# A8107M register map
Vendor: Amiccom Electronics Co., Ltd.; Series: A8107M; File version: 1.0
CPU: CM0 r0p0, little endian, no MPU, no FPU, 2 interrupt priority bits
Registers are 32-bit, read-write, reset 0x0 unless marked. A register's access mark holds for its fields unless they carry their own. Offsets are from the block's base; [hi:lo] are bit positions.

## GPIO0 (part 1 of 2) — General Purpose I/O
Base 0x40010000
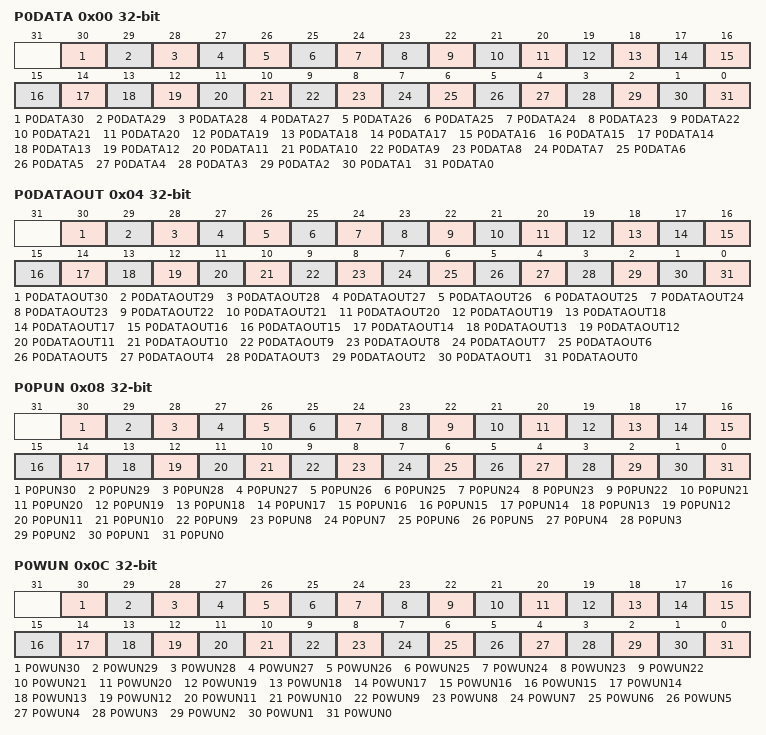
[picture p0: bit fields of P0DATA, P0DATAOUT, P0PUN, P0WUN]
0x00 P0DATA — Port 0 Data Register
  [30] P0DATA30 — Data of GPIO0.30
    0=GPIO0.30 is 0; 1=GPIO0.30 is 1
  [29] P0DATA29 — Data of GPIO0.29
    0=GPIO0.29 is 0; 1=GPIO0.29 is 1
  [28] P0DATA28 — Data of GPIO0.28
    0=GPIO0.28 is 0; 1=GPIO0.28 is 1
  [27] P0DATA27 — Data of GPIO0.27
    0=GPIO0.27 is 0; 1=GPIO0.27 is 1
  [26] P0DATA26 — Data of GPIO0.26
    0=GPIO0.26 is 0; 1=GPIO0.26 is 1
  [25] P0DATA25 — Data of GPIO0.25
    0=GPIO0.25 is 0; 1=GPIO0.25 is 1
  [24] P0DATA24 — Data of GPIO0.24
    0=GPIO0.24 is 0; 1=GPIO0.24 is 1
  [23] P0DATA23 — Data of GPIO0.23
    0=GPIO0.23 is 0; 1=GPIO0.23 is 1
  [22] P0DATA22 — Data of GPIO0.22
    0=GPIO0.22 is 0; 1=GPIO0.22 is 1
  [21] P0DATA21 — Data of GPIO0.21
    0=GPIO0.21 is 0; 1=GPIO0.21 is 1
  [20] P0DATA20 — Data of GPIO0.20
    0=GPIO0.20 is 0; 1=GPIO0.20 is 1
  [19] P0DATA19 — Data of GPIO0.19
    0=GPIO0.19 is 0; 1=GPIO0.19 is 1
  [18] P0DATA18 — Data of GPIO0.18
    0=GPIO0.18 is 0; 1=GPIO0.18 is 1
  [17] P0DATA17 — Data of GPIO0.17
    0=GPIO0.17 is 0; 1=GPIO0.17 is 1
  [16] P0DATA16 — Data of GPIO0.16
    0=GPIO0.16 is 0; 1=GPIO0.16 is 1
  [15] P0DATA15 — Data of GPIO0.15
    0=GPIO0.15 is 0; 1=GPIO0.15 is 1
  [14] P0DATA14 — Data of GPIO0.14
    0=GPIO0.14 is 0; 1=GPIO0.14 is 1
  [13] P0DATA13 — Data of GPIO0.13
    0=GPIO0.13 is 0; 1=GPIO0.13 is 1
  [12] P0DATA12 — Data of GPIO0.12
    0=GPIO0.12 is 0; 1=GPIO0.12 is 1
  [11] P0DATA11 — Data of GPIO0.11
    0=GPIO0.11 is 0; 1=GPIO0.11 is 1
  [10] P0DATA10 — Data of GPIO0.10
    0=GPIO0.10 is 0; 1=GPIO0.10 is 1
  [9] P0DATA9 — Data of GPIO0.9
    0=GPIO0.9 is 0; 1=GPIO0.9 is 1
  [8] P0DATA8 — Data of GPIO0.8
    0=GPIO0.8 is 0; 1=GPIO0.8 is 1
  [7] P0DATA7 — Data of GPIO0.7
    0=GPIO0.7 is 0; 1=GPIO0.7 is 1
  [6] P0DATA6 — Data of GPIO0.6
    0=GPIO0.6 is 0; 1=GPIO0.6 is 1
  [5] P0DATA5 — Data of GPIO0.5
    0=GPIO0.5 is 0; 1=GPIO0.5 is 1
  [4] P0DATA4 — Data of GPIO0.4
    0=GPIO0.4 is 0; 1=GPIO0.4 is 1
  [3] P0DATA3 — Data of GPIO0.3
    0=GPIO0.3 is 0; 1=GPIO0.3 is 1
  [2] P0DATA2 — Data of GPIO0.2
    0=GPIO0.2 is 0; 1=GPIO0.2 is 1
  [1] P0DATA1 — Data of GPIO0.1
    0=GPIO0.1 is 0; 1=GPIO0.1 is 1
  [0] P0DATA0 — Data of GPIO0.0
    0=GPIO0.0 is 0; 1=GPIO0.0 is 1
0x00 P0DATA_PIN (reset mask 0x7FFFFFFF) (alternate view of P0DATA) — Port 0 Data Register access by Pin
0x04 P0DATAOUT — Port 0 Data Out Register
  [30] P0DATAOUT30 — Data Out of GPIO0.30
    0=GPIO0.30 is 0; 1=GPIO0.30 is 1
  [29] P0DATAOUT29 — Data Out of GPIO0.29
    0=GPIO0.29 is 0; 1=GPIO0.29 is 1
  [28] P0DATAOUT28 — Data Out of GPIO0.28
    0=GPIO0.28 is 0; 1=GPIO0.28 is 1
  [27] P0DATAOUT27 — Data Out of GPIO0.27
    0=GPIO0.27 is 0; 1=GPIO0.27 is 1
  [26] P0DATAOUT26 — Data Out of GPIO0.26
    0=GPIO0.26 is 0; 1=GPIO0.26 is 1
  [25] P0DATAOUT25 — Data Out of GPIO0.25
    0=GPIO0.25 is 0; 1=GPIO0.25 is 1
  [24] P0DATAOUT24 — Data Out of GPIO0.24
    0=GPIO0.24 is 0; 1=GPIO0.24 is 1
  [23] P0DATAOUT23 — Data Out of GPIO0.23
    0=GPIO0.23 is 0; 1=GPIO0.23 is 1
  [22] P0DATAOUT22 — Data Out of GPIO0.22
    0=GPIO0.22 is 0; 1=GPIO0.22 is 1
  [21] P0DATAOUT21 — Data Out of GPIO0.21
    0=GPIO0.21 is 0; 1=GPIO0.21 is 1
  [20] P0DATAOUT20 — Data Out of GPIO0.20
    0=GPIO0.20 is 0; 1=GPIO0.20 is 1
  [19] P0DATAOUT19 — Data Out of GPIO0.19
    0=GPIO0.19 is 0; 1=GPIO0.19 is 1
  [18] P0DATAOUT18 — Data Out of GPIO0.18
    0=GPIO0.18 is 0; 1=GPIO0.18 is 1
  [17] P0DATAOUT17 — Data Out of GPIO0.17
    0=GPIO0.17 is 0; 1=GPIO0.17 is 1
  [16] P0DATAOUT16 — Data Out of GPIO0.16
    0=GPIO0.16 is 0; 1=GPIO0.16 is 1
  [15] P0DATAOUT15 — Data Out of GPIO0.15
    0=GPIO0.15 is 0; 1=GPIO0.15 is 1
  [14] P0DATAOUT14 — Data Out of GPIO0.14
    0=GPIO0.14 is 0; 1=GPIO0.14 is 1
  [13] P0DATAOUT13 — Data Out of GPIO0.13
    0=GPIO0.13 is 0; 1=GPIO0.13 is 1
  [12] P0DATAOUT12 — Data Out of GPIO0.12
    0=GPIO0.12 is 0; 1=GPIO0.12 is 1
  [11] P0DATAOUT11 — Data Out of GPIO0.11
    0=GPIO0.11 is 0; 1=GPIO0.11 is 1
  [10] P0DATAOUT10 — Data Out of GPIO0.10
    0=GPIO0.10 is 0; 1=GPIO0.10 is 1
  [9] P0DATAOUT9 — Data Out of GPIO0.9
    0=GPIO0.9 is 0; 1=GPIO0.9 is 1
  [8] P0DATAOUT8 — Data Out of GPIO0.8
    0=GPIO0.8 is 0; 1=GPIO0.8 is 1
  [7] P0DATAOUT7 — Data Out of GPIO0.7
    0=GPIO0.7 is 0; 1=GPIO0.7 is 1
  [6] P0DATAOUT6 — Data Out of GPIO0.6
    0=GPIO0.6 is 0; 1=GPIO0.6 is 1
  [5] P0DATAOUT5 — Data Out of GPIO0.5
    0=GPIO0.5 is 0; 1=GPIO0.5 is 1
  [4] P0DATAOUT4 — Data Out of GPIO0.4
    0=GPIO0.4 is 0; 1=GPIO0.4 is 1
  [3] P0DATAOUT3 — Data Out of GPIO0.3
    0=GPIO0.3 is 0; 1=GPIO0.3 is 1
  [2] P0DATAOUT2 — Data Out of GPIO0.2
    0=GPIO0.2 is 0; 1=GPIO0.2 is 1
  [1] P0DATAOUT1 — Data Out of GPIO0.1
    0=GPIO0.1 is 0; 1=GPIO0.1 is 1
  [0] P0DATAOUT0 — Data Out of GPIO0.0
    0=GPIO0.0 is 0; 1=GPIO0.0 is 1
0x04 P0DATAOUT_PIN (reset mask 0x7FFFFFFF) (alternate view of P0DATAOUT) — Port 0 Data Out Register access by Pin
0x08 P0PUN — Port 0 Pull Up Not Register
  [30] P0PUN30 — Pull Up of GPIO0.30
    0=Pull Up of GPIO0.30 is enable; 1=Pull Up of GPIO0.30 is disable
  [29] P0PUN29 — Pull Up of GPIO0.29
    0=Pull Up of GPIO0.29 is enable; 1=Pull Up of GPIO0.29 is disable
  [28] P0PUN28 — Pull Up of GPIO0.28
    0=Pull Up of GPIO0.28 is enable; 1=Pull Up of GPIO0.28 is disable
  [27] P0PUN27 — Pull Up of GPIO0.27
    0=Pull Up of GPIO0.27 is enable; 1=Pull Up of GPIO0.27 is disable
  [26] P0PUN26 — Pull Up of GPIO0.26
    0=Pull Up of GPIO0.26 is enable; 1=Pull Up of GPIO0.26 is disable
  [25] P0PUN25 — Pull Up of GPIO0.25
    0=Pull Up of GPIO0.25 is enable; 1=Pull Up of GPIO0.25 is disable
  [24] P0PUN24 — Pull Up of GPIO0.24
    0=Pull Up of GPIO0.24 is enable; 1=Pull Up of GPIO0.24 is disable
  [23] P0PUN23 — Pull Up of GPIO0.23
    0=Pull Up of GPIO0.23 is enable; 1=Pull Up of GPIO0.23 is disable
  [22] P0PUN22 — Pull Up of GPIO0.22
    0=Pull Up of GPIO0.22 is enable; 1=Pull Up of GPIO0.22 is disable
  [21] P0PUN21 — Pull Up of GPIO0.21
    0=Pull Up of GPIO0.21 is enable; 1=Pull Up of GPIO0.21 is disable
  [20] P0PUN20 — Pull Up of GPIO0.20
    0=Pull Up of GPIO0.20 is enable; 1=Pull Up of GPIO0.20 is disable
  [19] P0PUN19 — Pull Up of GPIO0.19
    0=Pull Up of GPIO0.19 is enable; 1=Pull Up of GPIO0.19 is disable
  [18] P0PUN18 — Pull Up of GPIO0.18
    0=Pull Up of GPIO0.18 is enable; 1=Pull Up of GPIO0.18 is disable
  [17] P0PUN17 — Pull Up of GPIO0.17
    0=Pull Up of GPIO0.17 is enable; 1=Pull Up of GPIO0.17 is disable
  [16] P0PUN16 — Pull Up of GPIO0.16
    0=Pull Up of GPIO0.16 is enable; 1=Pull Up of GPIO0.16 is disable
  [15] P0PUN15 — Pull Up of GPIO0.15
    0=Pull Up of GPIO0.15 is enable; 1=Pull Up of GPIO0.15 is disable
  [14] P0PUN14 — Pull Up of GPIO0.14
    0=Pull Up of GPIO0.14 is enable; 1=Pull Up of GPIO0.14 is disable
  [13] P0PUN13 — Pull Up of GPIO0.13
    0=Pull Up of GPIO0.13 is enable; 1=Pull Up of GPIO0.13 is disable
  [12] P0PUN12 — Pull Up of GPIO0.12
    0=Pull Up of GPIO0.12 is enable; 1=Pull Up of GPIO0.12 is disable
  [11] P0PUN11 — Pull Up of GPIO0.11
    0=Pull Up of GPIO0.11 is enable; 1=Pull Up of GPIO0.11 is disable
  [10] P0PUN10 — Pull Up of GPIO0.10
    0=Pull Up of GPIO0.10 is enable; 1=Pull Up of GPIO0.10 is disable
  [9] P0PUN9 — Pull Up of GPIO0.9
    0=Pull Up of GPIO0.9 is enable; 1=Pull Up of GPIO0.9 is disable
  [8] P0PUN8 — Pull Up of GPIO0.8
    0=Pull Up of GPIO0.8 is enable; 1=Pull Up of GPIO0.8 is disable
  [7] P0PUN7 — Pull Up of GPIO0.7
    0=Pull Up of GPIO0.7 is enable; 1=Pull Up of GPIO0.7 is disable
  [6] P0PUN6 — Pull Up of GPIO0.6
    0=Pull Up of GPIO0.6 is enable; 1=Pull Up of GPIO0.6 is disable
  [5] P0PUN5 — Pull Up of GPIO0.5
    0=Pull Up of GPIO0.5 is enable; 1=Pull Up of GPIO0.5 is disable
  [4] P0PUN4 — Pull Up of GPIO0.4
    0=Pull Up of GPIO0.4 is enable; 1=Pull Up of GPIO0.4 is disable
  [3] P0PUN3 — Pull Up of GPIO0.3
    0=Pull Up of GPIO0.3 is enable; 1=Pull Up of GPIO0.3 is disable
  [2] P0PUN2 — Pull Up of GPIO0.2
    0=Pull Up of GPIO0.2 is enable; 1=Pull Up of GPIO0.2 is disable
  [1] P0PUN1 — Pull Up of GPIO0.1
    0=Pull Up of GPIO0.1 is enable; 1=Pull Up of GPIO0.1 is disable
  [0] P0PUN0 — Pull Up of GPIO0.0
    0=Pull Up of GPIO0.0 is enable; 1=Pull Up of GPIO0.0 is disable
0x08 P0PUN_PIN (reset mask 0x7FFFFFFF) (alternate view of P0PUN) — Port 0 Pull Up Not Register access by Pin
0x0C P0WUN — Port 0 Wakeup Enable Not Register
  [30] P0WUN30 — Wakeup of GPIO0.30
    0=Wakeup of GPIO0.30 is enable; 1=Wakeup of GPIO0.30 is disable
  [29] P0WUN29 — Wakeup of GPIO0.29
    0=Wakeup of GPIO0.29 is enable; 1=Wakeup of GPIO0.29 is disable
  [28] P0WUN28 — Wakeup of GPIO0.28
    0=Wakeup of GPIO0.28 is enable; 1=Wakeup of GPIO0.28 is disable
  [27] P0WUN27 — Wakeup of GPIO0.27
    0=Wakeup of GPIO0.27 is enable; 1=Wakeup of GPIO0.27 is disable
  [26] P0WUN26 — Wakeup of GPIO0.26
    0=Wakeup of GPIO0.26 is enable; 1=Wakeup of GPIO0.26 is disable
  [25] P0WUN25 — Wakeup of GPIO0.25
    0=Wakeup of GPIO0.25 is enable; 1=Wakeup of GPIO0.25 is disable
  [24] P0WUN24 — Wakeup of GPIO0.24
    0=Wakeup of GPIO0.24 is enable; 1=Wakeup of GPIO0.24 is disable
  [23] P0WUN23 — Wakeup of GPIO0.23
    0=Wakeup of GPIO0.23 is enable; 1=Wakeup of GPIO0.23 is disable
  [22] P0WUN22 — Wakeup of GPIO0.22
    0=Wakeup of GPIO0.22 is enable; 1=Wakeup of GPIO0.22 is disable
  [21] P0WUN21 — Wakeup of GPIO0.21
    0=Wakeup of GPIO0.21 is enable; 1=Wakeup of GPIO0.21 is disable
  [20] P0WUN20 — Wakeup of GPIO0.20
    0=Wakeup of GPIO0.20 is enable; 1=Wakeup of GPIO0.20 is disable
  [19] P0WUN19 — Wakeup of GPIO0.19
    0=Wakeup of GPIO0.19 is enable; 1=Wakeup of GPIO0.19 is disable
  [18] P0WUN18 — Wakeup of GPIO0.18
    0=Wakeup of GPIO0.18 is enable; 1=Wakeup of GPIO0.18 is disable
  [17] P0WUN17 — Wakeup of GPIO0.17
    0=Wakeup of GPIO0.17 is enable; 1=Wakeup of GPIO0.17 is disable
  [16] P0WUN16 — Wakeup of GPIO0.16
    0=Wakeup of GPIO0.16 is enable; 1=Wakeup of GPIO0.16 is disable
  [15] P0WUN15 — Wakeup of GPIO0.15
    0=Wakeup of GPIO0.15 is enable; 1=Wakeup of GPIO0.15 is disable
  [14] P0WUN14 — Wakeup of GPIO0.14
    0=Wakeup of GPIO0.14 is enable; 1=Wakeup of GPIO0.14 is disable
  [13] P0WUN13 — Wakeup of GPIO0.13
    0=Wakeup of GPIO0.13 is enable; 1=Wakeup of GPIO0.13 is disable
  [12] P0WUN12 — Wakeup of GPIO0.12
    0=Wakeup of GPIO0.12 is enable; 1=Wakeup of GPIO0.12 is disable
  [11] P0WUN11 — Wakeup of GPIO0.11
    0=Wakeup of GPIO0.11 is enable; 1=Wakeup of GPIO0.11 is disable
  [10] P0WUN10 — Wakeup of GPIO0.10
    0=Wakeup of GPIO0.10 is enable; 1=Wakeup of GPIO0.10 is disable
  [9] P0WUN9 — Wakeup of GPIO0.9
    0=Wakeup of GPIO0.9 is enable; 1=Wakeup of GPIO0.9 is disable
  [8] P0WUN8 — Wakeup of GPIO0.8
    0=Wakeup of GPIO0.8 is enable; 1=Wakeup of GPIO0.8 is disable
  [7] P0WUN7 — Wakeup of GPIO0.7
    0=Wakeup of GPIO0.7 is enable; 1=Wakeup of GPIO0.7 is disable
  [6] P0WUN6 — Wakeup of GPIO0.6
    0=Wakeup of GPIO0.6 is enable; 1=Wakeup of GPIO0.6 is disable
  [5] P0WUN5 — Wakeup of GPIO0.5
    0=Wakeup of GPIO0.5 is enable; 1=Wakeup of GPIO0.5 is disable
  [4] P0WUN4 — Wakeup of GPIO0.4
    0=Wakeup of GPIO0.4 is enable; 1=Wakeup of GPIO0.4 is disable
  [3] P0WUN3 — Wakeup of GPIO0.3
    0=Wakeup of GPIO0.3 is enable; 1=Wakeup of GPIO0.3 is disable
  [2] P0WUN2 — Wakeup of GPIO0.2
    0=Wakeup of GPIO0.2 is enable; 1=Wakeup of GPIO0.2 is disable
  [1] P0WUN1 — Wakeup of GPIO0.1
    0=Wakeup of GPIO0.1 is enable; 1=Wakeup of GPIO0.1 is disable
  [0] P0WUN0 — Wakeup of GPIO0.0
    0=Wakeup of GPIO0.0 is enable; 1=Wakeup of GPIO0.0 is disable
0x0C P0WUN_PIN (reset mask 0x7FFFFFFF) (alternate view of P0WUN) — Port 0 Wakeup Enable Not Register access by Pin
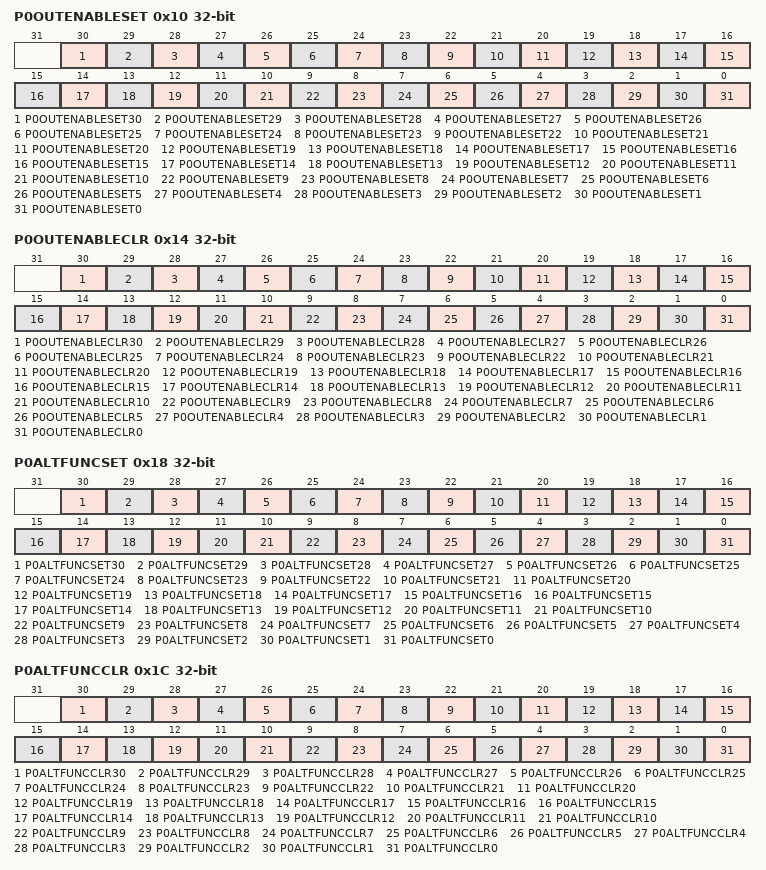
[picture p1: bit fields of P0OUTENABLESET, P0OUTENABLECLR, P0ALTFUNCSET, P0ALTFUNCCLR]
0x10 P0OUTENABLESET — Port 0 Output Enable Set Register
  [30] P0OUTENABLESET30 — Output Enable Clear of GPIO0.30
    0=No effect; 1=Output Enable Clear of GPIO0.30
  [29] P0OUTENABLESET29 — Output Enable Clear of GPIO0.29
    0=No effect; 1=Output Enable Clear of GPIO0.29
  [28] P0OUTENABLESET28 — Output Enable Clear of GPIO0.28
    0=No effect; 1=Output Enable Clear of GPIO0.28
  [27] P0OUTENABLESET27 — Output Enable Clear of GPIO0.27
    0=No effect; 1=No effect
  [26] P0OUTENABLESET26 — Output Enable Clear of GPIO0.26
    0=No effect; 1=Output Enable Clear of GPIO0.26
  [25] P0OUTENABLESET25 — Output Enable Clear of GPIO0.25
    0=No effect; 1=Output Enable Clear of GPIO0.25
  [24] P0OUTENABLESET24 — Output Enable Clear of GPIO0.24
    0=No effect; 1=Output Enable Clear of GPIO0.24
  [23] P0OUTENABLESET23 — Output Enable Clear of GPIO0.23
    0=No effect; 1=Output Enable Clear of GPIO0.23
  [22] P0OUTENABLESET22 — Output Enable Clear of GPIO0.22
    0=No effect; 1=Output Enable Clear of GPIO0.22
  [21] P0OUTENABLESET21 — Output Enable Clear of GPIO0.21
    0=No effect; 1=Output Enable Clear of GPIO0.21
  [20] P0OUTENABLESET20 — Output Enable Clear of GPIO0.20
    0=No effect; 1=Output Enable Clear of GPIO0.20
  [19] P0OUTENABLESET19 — Output Enable Clear of GPIO0.19
    0=No effect; 1=Output Enable Clear of GPIO0.19
  [18] P0OUTENABLESET18 — Output Enable Clear of GPIO0.18
    0=No effect; 1=Output Enable Clear of GPIO0.18
  [17] P0OUTENABLESET17 — Output Enable Clear of GPIO0.17
    0=No effect; 1=Output Enable Clear of GPIO0.17
  [16] P0OUTENABLESET16 — Output Enable Clear of GPIO0.16
    0=No effect; 1=Output Enable Clear of GPIO0.16
  [15] P0OUTENABLESET15 — Output Enable Clear of GPIO0.15
    0=No effect; 1=Output Enable Clear of GPIO0.15
  [14] P0OUTENABLESET14 — Output Enable Clear of GPIO0.14
    0=No effect; 1=Output Enable Clear of GPIO0.14
  [13] P0OUTENABLESET13 — Output Enable Clear of GPIO0.13
    0=No effect; 1=Output Enable Clear of GPIO0.13
  [12] P0OUTENABLESET12 — Output Enable Clear of GPIO0.12
    0=No effect; 1=Output Enable Clear of GPIO0.12
  [11] P0OUTENABLESET11 — Output Enable Clear of GPIO0.11
    0=No effect; 1=Output Enable Clear of GPIO0.11
  [10] P0OUTENABLESET10 — Output Enable Clear of GPIO0.10
    0=No effect; 1=Output Enable Clear of GPIO0.10
  [9] P0OUTENABLESET9 — Output Enable Clear of GPIO0.9
    0=No effect; 1=Output Enable Clear of GPIO0.9
  [8] P0OUTENABLESET8 — Output Enable Clear of GPIO0.8
    0=No effect; 1=Output Enable Clear of GPIO0.8
  [7] P0OUTENABLESET7 — Output Enable Clear of GPIO0.7
    0=No effect; 1=Output Enable Clear of GPIO0.7
  [6] P0OUTENABLESET6 — Output Enable Clear of GPIO0.6
    0=No effect; 1=Output Enable Clear of GPIO0.6
  [5] P0OUTENABLESET5 — Output Enable Clear of GPIO0.5
    0=No effect; 1=Output Enable Clear of GPIO0.5
  [4] P0OUTENABLESET4 — Output Enable Clear of GPIO0.4
    0=No effect; 1=Output Enable Clear of GPIO0.4
  [3] P0OUTENABLESET3 — Output Enable Clear of GPIO0.3
    0=No effect; 1=Output Enable Clear of GPIO0.3
  [2] P0OUTENABLESET2 — Output Enable Clear of GPIO0.2
    0=No effect; 1=Output Enable Clear of GPIO0.2
  [1] P0OUTENABLESET1 — Output Enable Clear of GPIO0.1
    0=No effect; 1=Output Enable Clear of GPIO0.1
  [0] P0OUTENABLESET0 — Output Enable Clear of GPIO0.0
    0=No effect; 1=Output Enable Clear of GPIO0.0
0x14 P0OUTENABLECLR — Port 0 Output Enable Clear Register
  [30] P0OUTENABLECLR30 — Output Enable Clear of GPIO0.30
    0=No effect; 1=Output Enable Clear of GPIO0.30
  [29] P0OUTENABLECLR29 — Output Enable Clear of GPIO0.29
    0=No effect; 1=Output Enable Clear of GPIO0.29
  [28] P0OUTENABLECLR28 — Output Enable Clear of GPIO0.28
    0=No effect; 1=Output Enable Clear of GPIO0.28
  [27] P0OUTENABLECLR27 — Output Enable Clear of GPIO0.27
    0=No effect; 1=No effect
  [26] P0OUTENABLECLR26 — Output Enable Clear of GPIO0.26
    0=No effect; 1=Output Enable Clear of GPIO0.26
  [25] P0OUTENABLECLR25 — Output Enable Clear of GPIO0.25
    0=No effect; 1=Output Enable Clear of GPIO0.25
  [24] P0OUTENABLECLR24 — Output Enable Clear of GPIO0.24
    0=No effect; 1=Output Enable Clear of GPIO0.24
  [23] P0OUTENABLECLR23 — Output Enable Clear of GPIO0.23
    0=No effect; 1=Output Enable Clear of GPIO0.23
  [22] P0OUTENABLECLR22 — Output Enable Clear of GPIO0.22
    0=No effect; 1=Output Enable Clear of GPIO0.22
  [21] P0OUTENABLECLR21 — Output Enable Clear of GPIO0.21
    0=No effect; 1=Output Enable Clear of GPIO0.21
  [20] P0OUTENABLECLR20 — Output Enable Clear of GPIO0.20
    0=No effect; 1=Output Enable Clear of GPIO0.20
  [19] P0OUTENABLECLR19 — Output Enable Clear of GPIO0.19
    0=No effect; 1=Output Enable Clear of GPIO0.19
  [18] P0OUTENABLECLR18 — Output Enable Clear of GPIO0.18
    0=No effect; 1=Output Enable Clear of GPIO0.18
  [17] P0OUTENABLECLR17 — Output Enable Clear of GPIO0.17
    0=No effect; 1=Output Enable Clear of GPIO0.17
  [16] P0OUTENABLECLR16 — Output Enable Clear of GPIO0.16
    0=No effect; 1=Output Enable Clear of GPIO0.16
  [15] P0OUTENABLECLR15 — Output Enable Clear of GPIO0.15
    0=No effect; 1=Output Enable Clear of GPIO0.15
  [14] P0OUTENABLECLR14 — Output Enable Clear of GPIO0.14
    0=No effect; 1=Output Enable Clear of GPIO0.14
  [13] P0OUTENABLECLR13 — Output Enable Clear of GPIO0.13
    0=No effect; 1=Output Enable Clear of GPIO0.13
  [12] P0OUTENABLECLR12 — Output Enable Clear of GPIO0.12
    0=No effect; 1=Output Enable Clear of GPIO0.12
  [11] P0OUTENABLECLR11 — Output Enable Clear of GPIO0.11
    0=No effect; 1=Output Enable Clear of GPIO0.11
  [10] P0OUTENABLECLR10 — Output Enable Clear of GPIO0.10
    0=No effect; 1=Output Enable Clear of GPIO0.10
  [9] P0OUTENABLECLR9 — Output Enable Clear of GPIO0.9
    0=No effect; 1=Output Enable Clear of GPIO0.9
  [8] P0OUTENABLECLR8 — Output Enable Clear of GPIO0.8
    0=No effect; 1=Output Enable Clear of GPIO0.8
  [7] P0OUTENABLECLR7 — Output Enable Clear of GPIO0.7
    0=No effect; 1=Output Enable Clear of GPIO0.7
  [6] P0OUTENABLECLR6 — Output Enable Clear of GPIO0.6
    0=No effect; 1=Output Enable Clear of GPIO0.6
  [5] P0OUTENABLECLR5 — Output Enable Clear of GPIO0.5
    0=No effect; 1=Output Enable Clear of GPIO0.5
  [4] P0OUTENABLECLR4 — Output Enable Clear of GPIO0.4
    0=No effect; 1=Output Enable Clear of GPIO0.4
  [3] P0OUTENABLECLR3 — Output Enable Clear of GPIO0.3
    0=No effect; 1=Output Enable Clear of GPIO0.3
  [2] P0OUTENABLECLR2 — Output Enable Clear of GPIO0.2
    0=No effect; 1=Output Enable Clear of GPIO0.2
  [1] P0OUTENABLECLR1 — Output Enable Clear of GPIO0.1
    0=No effect; 1=Output Enable Clear of GPIO0.1
  [0] P0OUTENABLECLR0 — Output Enable Clear of GPIO0.0
    0=No effect; 1=Output enable clear of GPIO0.0
0x18 P0ALTFUNCSET — Port 0 Alternative Function Set Register
  [30] P0ALTFUNCSET30 — Alternative Function Set of GPIO0.30
    0=No effect; 1=Alternative Function Set of GPIO0.30
  [29] P0ALTFUNCSET29 — Alternative Function Set of GPIO0.29
    0=No effect; 1=Alternative Function Set of GPIO0.29
  [28] P0ALTFUNCSET28 — Alternative Function Set of GPIO0.28
    0=No effect; 1=Alternative Function Set of GPIO0.28
  [27] P0ALTFUNCSET27 — Alternative Function Set of GPIO0.27
    0=No effect; 1=No effect
  [26] P0ALTFUNCSET26 — Alternative Function Set of GPIO0.26
    0=No effect; 1=Alternative Function Set of GPIO0.26
  [25] P0ALTFUNCSET25 — Alternative Function Set of GPIO0.25
    0=No effect; 1=Alternative Function Set of GPIO0.25
  [24] P0ALTFUNCSET24 — Alternative Function Set of GPIO0.24
    0=No effect; 1=Alternative Function Set of GPIO0.24
  [23] P0ALTFUNCSET23 — Alternative Function Set of GPIO0.23
    0=No effect; 1=Alternative Function Set of GPIO0.23
  [22] P0ALTFUNCSET22 — Alternative Function Set of GPIO0.22
    0=No effect; 1=Alternative Function Set of GPIO0.22
  [21] P0ALTFUNCSET21 — Alternative Function Set of GPIO0.21
    0=No effect; 1=Alternative Function Set of GPIO0.21
  [20] P0ALTFUNCSET20 — Alternative Function Set of GPIO0.20
    0=No effect; 1=Alternative Function Set of GPIO0.20
  [19] P0ALTFUNCSET19 — Alternative Function Set of GPIO0.19
    0=No effect; 1=Alternative Function Set of GPIO0.19
  [18] P0ALTFUNCSET18 — Alternative Function Set of GPIO0.18
    0=No effect; 1=Alternative Function Set of GPIO0.18
  [17] P0ALTFUNCSET17 — Alternative Function Set of GPIO0.17
    0=No effect; 1=Alternative Function Set of GPIO0.17
  [16] P0ALTFUNCSET16 — Alternative Function Set of GPIO0.16
    0=No effect; 1=Alternative Function Set of GPIO0.16
  [15] P0ALTFUNCSET15 — Alternative Function Set of GPIO0.15
    0=No effect; 1=Alternative Function Set of GPIO0.15
  [14] P0ALTFUNCSET14 — Alternative Function Set of GPIO0.14
    0=No effect; 1=Alternative Function Set of GPIO0.14
  [13] P0ALTFUNCSET13 — Alternative Function Set of GPIO0.13
    0=No effect; 1=Alternative Function Set of GPIO0.13
  [12] P0ALTFUNCSET12 — Alternative Function Set of GPIO0.12
    0=No effect; 1=Alternative Function Set of GPIO0.12
  [11] P0ALTFUNCSET11 — Alternative Function Set of GPIO0.11
    0=No effect; 1=Alternative Function Set of GPIO0.11
  [10] P0ALTFUNCSET10 — Alternative Function Set of GPIO0.10
    0=No effect; 1=Alternative Function Set of GPIO0.10
  [9] P0ALTFUNCSET9 — Alternative Function Set of GPIO0.9
    0=No effect; 1=Alternative Function Set of GPIO0.9
  [8] P0ALTFUNCSET8 — Alternative Function Set of GPIO0.8
    0=No effect; 1=Alternative Function Set of GPIO0.8
  [7] P0ALTFUNCSET7 — Alternative Function Set of GPIO0.7
    0=No effect; 1=Alternative Function Set of GPIO0.7
  [6] P0ALTFUNCSET6 — Alternative Function Set of GPIO0.6
    0=No effect; 1=Alternative Function Set of GPIO0.6
  [5] P0ALTFUNCSET5 — Alternative Function Set of GPIO0.5
    0=No effect; 1=Alternative Function Set of GPIO0.5
  [4] P0ALTFUNCSET4 — Alternative Function Set of GPIO0.4
    0=No effect; 1=Alternative Function Set of GPIO0.4
  [3] P0ALTFUNCSET3 — Alternative Function Set of GPIO0.3
    0=No effect; 1=Alternative Function Set of GPIO0.3
  [2] P0ALTFUNCSET2 — Alternative Function Set of GPIO0.2
    0=No effect; 1=Alternative Function Set of GPIO0.2
  [1] P0ALTFUNCSET1 — Alternative Function Set of GPIO0.1
    0=No effect; 1=Alternative Function Set of GPIO0.1
  [0] P0ALTFUNCSET0 — Alternative Function Set of GPIO0.0
    0=No effect; 1=Alternative Function Set of GPIO0.0
0x1C P0ALTFUNCCLR — Port 0 Alternative Function Clear Register
  [30] P0ALTFUNCCLR30 — Alternative Function Clear of GPIO0.30
    0=No effect; 1=Alternative Function Clear of GPIO0.30
  [29] P0ALTFUNCCLR29 — Alternative Function Clear of GPIO0.29
    0=No effect; 1=Alternative Function Clear of GPIO0.29
  [28] P0ALTFUNCCLR28 — Alternative Function Clear of GPIO0.28
    0=No effect; 1=Alternative Function Clear of GPIO0.28
  [27] P0ALTFUNCCLR27 — Alternative Function Clear of GPIO0.27
    0=No effect; 1=No effect
  [26] P0ALTFUNCCLR26 — Alternative Function Clear of GPIO0.26
    0=No effect; 1=Alternative Function Clear of GPIO0.26
  [25] P0ALTFUNCCLR25 — Alternative Function Clear of GPIO0.25
    0=No effect; 1=Alternative Function Clear of GPIO0.25
  [24] P0ALTFUNCCLR24 — Alternative Function Clear of GPIO0.24
    0=No effect; 1=Alternative Function Clear of GPIO0.24
  [23] P0ALTFUNCCLR23 — Alternative Function Clear of GPIO0.23
    0=No effect; 1=Alternative Function Clear of GPIO0.23
  [22] P0ALTFUNCCLR22 — Alternative Function Clear of GPIO0.22
    0=No effect; 1=Alternative Function Clear of GPIO0.22
  [21] P0ALTFUNCCLR21 — Alternative Function Clear of GPIO0.21
    0=No effect; 1=Alternative Function Clear of GPIO0.21
  [20] P0ALTFUNCCLR20 — Alternative Function Clear of GPIO0.20
    0=No effect; 1=Alternative Function Clear of GPIO0.20
  [19] P0ALTFUNCCLR19 — Alternative Function Clear of GPIO0.19
    0=No effect; 1=Alternative Function Clear of GPIO0.19
  [18] P0ALTFUNCCLR18 — Alternative Function Clear of GPIO0.18
    0=No effect; 1=Alternative Function Clear of GPIO0.18
  [17] P0ALTFUNCCLR17 — Alternative Function Clear of GPIO0.17
    0=No effect; 1=Alternative Function Clear of GPIO0.17
  [16] P0ALTFUNCCLR16 — Alternative Function Clear of GPIO0.16
    0=No effect; 1=Alternative Function Clear of GPIO0.16
  [15] P0ALTFUNCCLR15 — Alternative Function Clear of GPIO0.15
    0=No effect; 1=Alternative Function Clear of GPIO0.15
  [14] P0ALTFUNCCLR14 — Alternative Function Clear of GPIO0.14
    0=No effect; 1=Alternative Function Clear of GPIO0.14
  [13] P0ALTFUNCCLR13 — Alternative Function Clear of GPIO0.13
    0=No effect; 1=Alternative Function Clear of GPIO0.13
  [12] P0ALTFUNCCLR12 — Alternative Function Clear of GPIO0.12
    0=No effect; 1=Alternative Function Clear of GPIO0.12
  [11] P0ALTFUNCCLR11 — Alternative Function Clear of GPIO0.11
    0=No effect; 1=Alternative Function Clear of GPIO0.11
  [10] P0ALTFUNCCLR10 — Alternative Function Clear of GPIO0.10
    0=No effect; 1=Alternative Function Clear of GPIO0.10
  [9] P0ALTFUNCCLR9 — Alternative Function Clear of GPIO0.9
    0=No effect; 1=Alternative Function Clear of GPIO0.9
  [8] P0ALTFUNCCLR8 — Alternative Function Clear of GPIO0.8
    0=No effect; 1=Alternative Function Clear of GPIO0.8
  [7] P0ALTFUNCCLR7 — Alternative Function Clear of GPIO0.7
    0=No effect; 1=Alternative Function Clear of GPIO0.7
  [6] P0ALTFUNCCLR6 — Alternative Function Clear of GPIO0.6
    0=No effect; 1=Alternative Function Clear of GPIO0.6
  [5] P0ALTFUNCCLR5 — Alternative Function Clear of GPIO0.5
    0=No effect; 1=Alternative Function Clear of GPIO0.5
  [4] P0ALTFUNCCLR4 — Alternative Function Clear of GPIO0.4
    0=No effect; 1=Alternative Function Clear of GPIO0.4
  [3] P0ALTFUNCCLR3 — Alternative Function Clear of GPIO0.3
    0=No effect; 1=Alternative Function Clear of GPIO0.3
  [2] P0ALTFUNCCLR2 — Alternative Function Clear of GPIO0.2
    0=No effect; 1=Alternative Function Clear of GPIO0.2
  [1] P0ALTFUNCCLR1 — Alternative Function Clear of GPIO0.1
    0=No effect; 1=Alternative Function Clear of GPIO0.1
  [0] P0ALTFUNCCLR0 — Alternative Function Clear of GPIO0.0
    0=No effect; 1=Alternative Function Clear of GPIO0.0
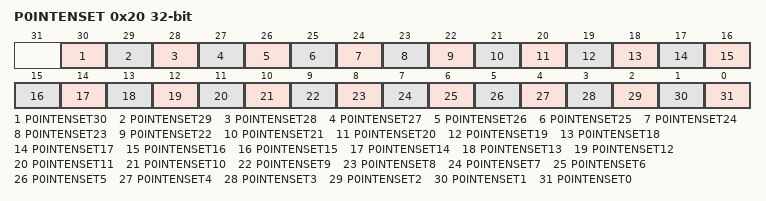
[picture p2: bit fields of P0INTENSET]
0x20 P0INTENSET — Port 0 Interrupt Enable Set Register
  [30] P0INTENSET30 — Interrupt Enable Set of GPIO0.30
    0=No effect; 1=Interrupt Enable Set of GPIO0.30
  [29] P0INTENSET29 — Interrupt Enable Set of GPIO0.29
    0=No effect; 1=Interrupt Enable Set of GPIO0.29
  [28] P0INTENSET28 — Interrupt Enable Set of GPIO0.28
    0=No effect; 1=Interrupt Enable Set of GPIO0.28
  [27] P0INTENSET27 — Interrupt Enable Set of GPIO0.27
    0=No effect; 1=No effect
  [26] P0INTENSET26 — Interrupt Enable Set of GPIO0.26
    0=No effect; 1=Interrupt Enable Set of GPIO0.26
  [25] P0INTENSET25 — Interrupt Enable Set of GPIO0.25
    0=No effect; 1=Interrupt Enable Set of GPIO0.25
  [24] P0INTENSET24 — Interrupt Enable Set of GPIO0.24
    0=No effect; 1=Interrupt Enable Set of GPIO0.24
  [23] P0INTENSET23 — Interrupt Enable Set of GPIO0.23
    0=No effect; 1=Interrupt Enable Set of GPIO0.23
  [22] P0INTENSET22 — Interrupt Enable Set of GPIO0.22
    0=No effect; 1=Interrupt Enable Set of GPIO0.22
  [21] P0INTENSET21 — Interrupt Enable Set of GPIO0.21
    0=No effect; 1=Interrupt Enable Set of GPIO0.21
  [20] P0INTENSET20 — Interrupt Enable Set of GPIO0.20
    0=No effect; 1=Interrupt Enable Set of GPIO0.20
  [19] P0INTENSET19 — Interrupt Enable Set of GPIO0.19
    0=No effect; 1=Interrupt Enable Set of GPIO0.19
  [18] P0INTENSET18 — Interrupt Enable Set of GPIO0.18
    0=No effect; 1=Interrupt Enable Set of GPIO0.18
  [17] P0INTENSET17 — Interrupt Enable Set of GPIO0.17
    0=No effect; 1=Interrupt Enable Set of GPIO0.17
  [16] P0INTENSET16 — Interrupt Enable Set of GPIO0.16
    0=No effect; 1=Interrupt Enable Set of GPIO0.16
  [15] P0INTENSET15 — Interrupt Enable Set of GPIO0.15
    0=No effect; 1=Interrupt Enable Set of GPIO0.15
  [14] P0INTENSET14 — Interrupt Enable Set of GPIO0.14
    0=No effect; 1=Interrupt Enable Set of GPIO0.14
  [13] P0INTENSET13 — Interrupt Enable Set of GPIO0.13
    0=No effect; 1=Interrupt Enable Set of GPIO0.13
  [12] P0INTENSET12 — Interrupt Enable Set of GPIO0.12
    0=No effect; 1=Interrupt Enable Set of GPIO0.12
  [11] P0INTENSET11 — Interrupt Enable Set of GPIO0.11
    0=No effect; 1=Interrupt Enable Set of GPIO0.11
  [10] P0INTENSET10 — Interrupt Enable Set of GPIO0.10
    0=No effect; 1=Interrupt Enable Set of GPIO0.10
  [9] P0INTENSET9 — Interrupt Enable Set of GPIO0.9
    0=No effect; 1=Interrupt Enable Set of GPIO0.9
  [8] P0INTENSET8 — Interrupt Enable Set of GPIO0.8
    0=No effect; 1=Interrupt Enable Set of GPIO0.8
  [7] P0INTENSET7 — Interrupt Enable Set of GPIO0.7
    0=No effect; 1=Interrupt Enable Set of GPIO0.7
  [6] P0INTENSET6 — Interrupt Enable Set of GPIO0.6
    0=No effect; 1=Interrupt Enable Set of GPIO0.6
  [5] P0INTENSET5 — Interrupt Enable Set of GPIO0.5
    0=No effect; 1=Interrupt Enable Set of GPIO0.5
  [4] P0INTENSET4 — Interrupt Enable Set of GPIO0.4
    0=No effect; 1=Interrupt Enable Set of GPIO0.4
  [3] P0INTENSET3 — Interrupt Enable Set of GPIO0.3
    0=No effect; 1=Interrupt Enable Set of GPIO0.3
  [2] P0INTENSET2 — Interrupt Enable Set of GPIO0.2
    0=No effect; 1=Interrupt Enable Set of GPIO0.2
  [1] P0INTENSET1 — Interrupt Enable Set of GPIO0.1
    0=No effect; 1=Interrupt Enable Set of GPIO0.1
  [0] P0INTENSET0 — Interrupt Enable Set of GPIO0.0
    0=No effect; 1=Interrupt Enable Set of GPIO0.0
